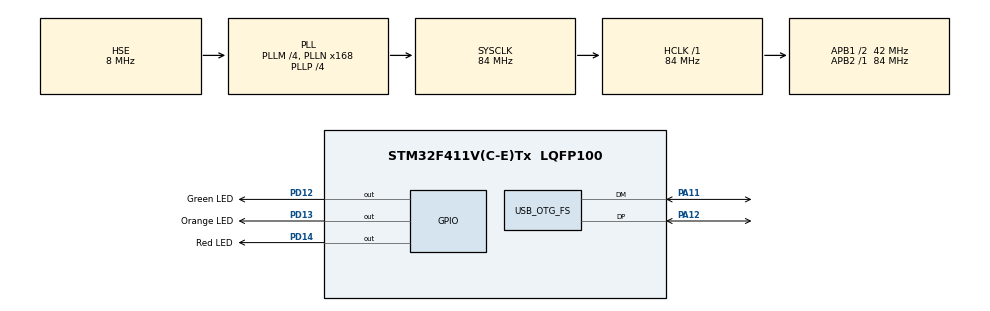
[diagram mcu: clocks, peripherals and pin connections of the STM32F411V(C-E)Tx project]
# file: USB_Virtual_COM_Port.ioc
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Mcu.Family=STM32F4
Mcu.Name=STM32F411V(C-E)Tx
Mcu.Package=LQFP100
NVIC.OTG_FS_IRQn=true\:0\:0\:false\:false\:true\:true\:true
NVIC.PriorityGroup=NVIC_PRIORITYGROUP_0
PA11.Mode=Device_Only
PA11.Signal=USB_OTG_FS_DM
PA12.Mode=Device_Only
PA12.Signal=USB_OTG_FS_DP
PD12.GPIO_Label=Green LED
PD12.Signal=GPIO_Output
PD13.GPIO_Label=Orange LED
PD13.Signal=GPIO_Output
PD14.GPIO_Label=Red LED
PD14.Signal=GPIO_Output
PH0\ -\ OSC_IN.Mode=HSE-External-Oscillator
PH0\ -\ OSC_IN.Signal=RCC_OSC_IN
PH1\ -\ OSC_OUT.Mode=HSE-External-Oscillator
PH1\ -\ OSC_OUT.Signal=RCC_OSC_OUT
ProjectManager.HeapSize=0x2000
ProjectManager.StackSize=0x4000
ProjectManager.TargetToolchain=MDK-ARM V5
RCC.48MHZClocksFreq_Value=48000000
RCC.AHBFreq_Value=84000000
RCC.APB1CLKDivider=RCC_HCLK_DIV2
RCC.APB1Freq_Value=42000000
RCC.APB1TimFreq_Value=84000000
RCC.APB2Freq_Value=84000000
RCC.APB2TimFreq_Value=84000000
RCC.CortexFreq_Value=84000000
RCC.HCLKFreq_Value=84000000
RCC.HSE_VALUE=8000000
RCC.HSI_VALUE=16000000
RCC.PLLI2SM=5
RCC.PLLI2SN=200
RCC.PLLM=4
RCC.PLLN=168
RCC.PLLP=RCC_PLLP_DIV4
RCC.PLLQ=7
RCC.SYSCLKFreq_VALUE=84000000
RCC.SYSCLKSource=RCC_SYSCLKSOURCE_PLLCLK
RCC.VCOOutputFreq_Value=336000000
USB_DEVICE.CLASS_NAME_FS=CDC
USB_DEVICE.VirtualMode=Cdc
USB_DEVICE.VirtualModeFS=Cdc_FS
USB_OTG_FS.VirtualMode=Device_Only
VP_USB_DEVICE_VS_USB_DEVICE_CDC_FS.Mode=CDC_FS
board=STM32F411E-DISCO

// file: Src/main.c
/* USER CODE BEGIN Header */
/**
  ******************************************************************************
  * @file           : main.c
  * @brief          : Main program body
  ******************************************************************************
  * @attention
  *
  * <h2><center>&copy; Copyright (c) 2019 STMicroelectronics.
  * All rights reserved.</center></h2>
  *
  * This software component is licensed by ST under Ultimate Liberty license
  * SLA0044, the "License"; You may not use this file except in compliance with
  * the License. You may obtain a copy of the License at:
  *                             www.st.com/SLA0044
  * STM32F411 Discovery OTG Virtual COM Port demo 115200bps
	* K.Kanas 22/8/2018
  ******************************************************************************
  */
/* USER CODE END Header */

#include "main.h"
#include "usb_device.h"

/* USER CODE BEGIN Includes */
#include "usbd_cdc_if.h"

/* USER CODE END Includes */

/* USER CODE BEGIN PV */

uint8_t buffer[100]=" Virtual COM Port Demo Press any key\r\n";

/* USER CODE END PV */

void SystemClock_Config(void);
static void MX_GPIO_Init(void);

int main(void)
{

  /* MCU Configuration--------------------------------------------------------*/

  /* Reset of all peripherals, Initializes the Flash interface and the Systick. */
  HAL_Init();

  /* Configure the system clock */
  SystemClock_Config();

  /* Initialize all configured peripherals */
  MX_GPIO_Init();
  MX_USB_DEVICE_Init();
 HAL_Delay(3000);
 CDC_Transmit_FS(buffer,strlen((char*)buffer ));

  /* Infinite loop */
  while (1)
  {
       //CDC_Transmit_FS(buffer,strlen((char*)buffer ));
	    //HAL_GPIO_TogglePin(GPIOD,GPIO_PIN_13);             //Toggle Orange LED
		  HAL_Delay(500);

  }
}

void SystemClock_Config(void)
{
  RCC_OscInitTypeDef RCC_OscInitStruct = {0};
  RCC_ClkInitTypeDef RCC_ClkInitStruct = {0};

  /** Configure the main internal regulator output voltage
  */
  __HAL_RCC_PWR_CLK_ENABLE();
  __HAL_PWR_VOLTAGESCALING_CONFIG(PWR_REGULATOR_VOLTAGE_SCALE1);
  /** Initializes the CPU, AHB and APB busses clocks
  */
  RCC_OscInitStruct.OscillatorType = RCC_OSCILLATORTYPE_HSE;
  RCC_OscInitStruct.HSEState = RCC_HSE_ON;
  RCC_OscInitStruct.PLL.PLLState = RCC_PLL_ON;
  RCC_OscInitStruct.PLL.PLLSource = RCC_PLLSOURCE_HSE;
  RCC_OscInitStruct.PLL.PLLM = 4;
  RCC_OscInitStruct.PLL.PLLN = 168;
  RCC_OscInitStruct.PLL.PLLP = RCC_PLLP_DIV4;
  RCC_OscInitStruct.PLL.PLLQ = 7;
  if (HAL_RCC_OscConfig(&RCC_OscInitStruct) != HAL_OK)
  {
    Error_Handler();
  }
  /** Initializes the CPU, AHB and APB busses clocks
  */
  RCC_ClkInitStruct.ClockType = RCC_CLOCKTYPE_HCLK|RCC_CLOCKTYPE_SYSCLK
                              |RCC_CLOCKTYPE_PCLK1|RCC_CLOCKTYPE_PCLK2;
  RCC_ClkInitStruct.SYSCLKSource = RCC_SYSCLKSOURCE_PLLCLK;
  RCC_ClkInitStruct.AHBCLKDivider = RCC_SYSCLK_DIV1;
  RCC_ClkInitStruct.APB1CLKDivider = RCC_HCLK_DIV2;
  RCC_ClkInitStruct.APB2CLKDivider = RCC_HCLK_DIV1;

  if (HAL_RCC_ClockConfig(&RCC_ClkInitStruct, FLASH_LATENCY_2) != HAL_OK)
  {
    Error_Handler();
  }
}

static void MX_GPIO_Init(void)
{
  GPIO_InitTypeDef GPIO_InitStruct = {0};

  /* GPIO Ports Clock Enable */
  __HAL_RCC_GPIOH_CLK_ENABLE();
  __HAL_RCC_GPIOD_CLK_ENABLE();
  __HAL_RCC_GPIOA_CLK_ENABLE();

  /*Configure GPIO pin Output Level */
  HAL_GPIO_WritePin(GPIOD, Green_LED_Pin|Orange_LED_Pin|Red_LED_Pin, GPIO_PIN_RESET);

  /*Configure GPIO pins : Green_LED_Pin Orange_LED_Pin Red_LED_Pin */
  GPIO_InitStruct.Pin = Green_LED_Pin|Orange_LED_Pin|Red_LED_Pin;
  GPIO_InitStruct.Mode = GPIO_MODE_OUTPUT_PP;
  GPIO_InitStruct.Pull = GPIO_NOPULL;
  GPIO_InitStruct.Speed = GPIO_SPEED_FREQ_LOW;
  HAL_GPIO_Init(GPIOD, &GPIO_InitStruct);

}

/* USER CODE BEGIN 4 */
void CDC_ReceiveCallback (uint8_t *buf,uint32_t len) /*Callback for receiving USB buffer*/

 {
     CDC_Transmit_FS(buf,len);
	   HAL_GPIO_TogglePin(GPIOD,GPIO_PIN_13);

 }

/* USER CODE END 4 */

void Error_Handler(void)
{
}

/************************ (C) COPYRIGHT STMicroelectronics *****END OF FILE****/
